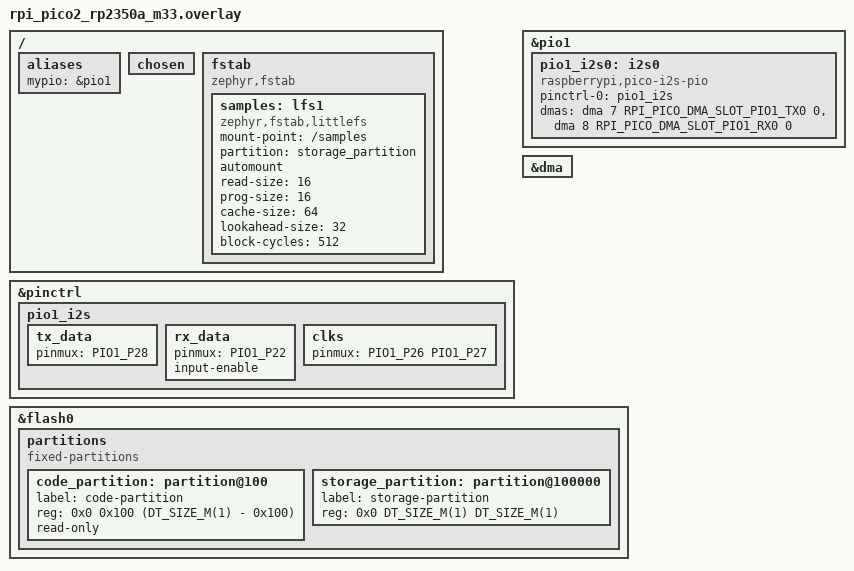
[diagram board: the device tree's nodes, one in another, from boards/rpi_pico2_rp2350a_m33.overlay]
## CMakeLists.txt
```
#-------------------------------------------------------------------------------
# Pocket Sampler Firmware 
#
# Copyright (c) 2021 Nordic Semiconductor ASA
# SPDX-License-Identifier: Apache-2.0

cmake_minimum_required(VERSION 3.13.1)
find_package(Zephyr REQUIRED HINTS $ENV{ZEPHYR_BASE})

project(app LANGUAGES C)

target_sources(app PRIVATE src/main.c)
```

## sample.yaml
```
sample:
  description: Pocket Sampler
  name: pocket-sampler 
common:
  build_only: true
  integration_platforms:
    - rp2040_zero
  depends_on:
    - usbd
tests:
  app.default: {}
  app.debug:
    extra_overlay_confs:
      - debug.conf
```

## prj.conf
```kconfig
CONFIG_GPIO=y

CONFIG_SHELL=y
CONFIG_GPIO_SHELL=y

CONFIG_FLASH=y
CONFIG_FLASH_MAP=y
CONFIG_FLASH_SHELL=y

CONFIG_FILE_SYSTEM=y
CONFIG_FILE_SYSTEM_LITTLEFS=y
CONFIG_FILE_SYSTEM_SHELL=y

CONFIG_DMA=y
CONFIG_I2S=y
CONFIG_COMPILER_SAVE_TEMPS=y

CONFIG_LOG=y
CONFIG_APP_LOG_LEVEL_DBG=y
CONFIG_I2S_LOG_LEVEL_DBG=y
CONFIG_DMA_LOG_LEVEL_DBG=y
CONFIG_FLASH_LOG_LEVEL_DBG=y
CONFIG_FS_LOG_LEVEL_DBG=y
```

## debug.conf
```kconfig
# Copyright (c) 2021 Nordic Semiconductor ASA
# SPDX-License-Identifier: Apache-2.0
#
# This is a Kconfig fragment which can be used to enable debug-related options
# in the application. See the README for more details.

# compiler
CONFIG_DEBUG_OPTIMIZATIONS=y

# native sim
CONFIG_EMUL=y
# CONFIG_FUSE_FS_ACCESS=y

# CONFIG_DISK_DRIVERS=y
# CONFIG_DISK_DRIVER_FLASH=y
# CONFIG_DISK_ACCESS=y
# CONFIG_FAT_FILESYSTEM_ELM=y
# CONFIG_MAIN_STACK_SIZE=2048

# logging
CONFIG_LOG=y
CONFIG_APP_LOG_LEVEL_DBG=y
CONFIG_DAC_LOG_LEVEL_OFF=y
```

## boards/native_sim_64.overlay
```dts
/ {
	aliases {
		mydac = &fake_dac;
	};
    fake_dac: dac_mock {
        compatible = "zephyr,dac-mock";
        status = "okay";
        #io-channel-cells = <1>;
    };

};
```

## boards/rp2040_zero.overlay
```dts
#include <dt-bindings/pinctrl/rpi-pico-rp2040-pinctrl.h>
#include <zephyr/dt-bindings/dma/rpi-pico-dma-rp2040.h>

/ {
	aliases {
		mypio = &pio1;
        
	};
	chosen {
		
    };
	
	fstab {
        compatible = "zephyr,fstab";
        samples: lfs1 {
            compatible = "zephyr,fstab,littlefs";
            mount-point = "/samples";
            partition = <&storage_partition>;
            automount;
            read-size = <16>;
            prog-size = <16>;
            cache-size = <64>;
            lookahead-size = <32>;
            block-cycles = <512>;
        };
    };
};


&pinctrl {
	pio1_i2s: pio1_i2s {
		tx_pins: tx_pins {
			//        DATA    CLK BASE  WS
			pinmux = <PIO1_P26 PIO1_P27 PIO1_P28>;
		};
	};

};

&pio1 { status = "okay";

	pio1_i2s0: i2s0 {
		pinctrl-0 = <&pio1_i2s>;
		pinctrl-names = "default";
		// TODO: Look over what these mean and that these values make sense
		#address-cells = <1>; 
		#size-cells = <0>;

		compatible = "raspberrypi,pico-i2s-pio";
		status = "okay";

		// TODO: Check how this works, but for now I believe that:
		//         channel      SLOT                  channel-config?
		//         number  (which corresponds to an IRQN)
		dmas = <&dma 7     RPI_PICO_DMA_SLOT_PIO1_TX0        0>;
		dma-names = "tx";
	};
};

&dma {
	status = "okay";
};

&flash0 {
	partitions {
		/*
		 * Usable flash. Starts at 0x100, after the bootloader. The partition
		 * size is 1MB minus the 0x100 bytes taken by the bootloader.
		 */
		code_partition: partition@100 {
			label = "code-partition";
			reg = <0x100 (DT_SIZE_M(1) - 0x100)>;
			read-only;
		};
		storage_partition: partition@100000 {
			label = "storage-partition";
			reg = <DT_SIZE_M(1) DT_SIZE_M(1)>;
		};
	};
};
```

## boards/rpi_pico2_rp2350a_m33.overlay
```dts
#include <dt-bindings/pinctrl/rpi-pico-rp2350a-pinctrl.h>
#include <zephyr/dt-bindings/dma/rpi-pico-dma-rp2350.h>

/ {
	aliases {
		mypio = &pio1;

	};
	chosen {

    };

	fstab {
        compatible = "zephyr,fstab";
        samples: lfs1 {
            compatible = "zephyr,fstab,littlefs";
            mount-point = "/samples";
            partition = <&storage_partition>;
            automount;
            read-size = <16>;
            prog-size = <16>;
            cache-size = <64>;
            lookahead-size = <32>;
            block-cycles = <512>;
        };
    };
};


&pinctrl {
	pio1_i2s: pio1_i2s {
		tx_data: tx_data {
			pinmux = <PIO1_P28>;
		};
		rx_data: rx_data {
			pinmux = <PIO1_P22>;
			/* Enable the pad input buffer so the PIO `in pins` can sample
			 * the external RX data line (off by default). */
			input-enable;
		};
		clks: clks {
			//        CLK BASE  (WS = CLK+1)
			pinmux = <PIO1_P26 PIO1_P27>;
		};
	};

};

&pio1 { status = "okay";

	pio1_i2s0: i2s0 {
		pinctrl-0 = <&pio1_i2s>;
		pinctrl-names = "default";
		// TODO: Look over what these mean and that these values make sense
		#address-cells = <1>;
		#size-cells = <0>;

		compatible = "raspberrypi,pico-i2s-pio";
		status = "okay";

		// TODO: Check how this works, but for now I believe that:
		//         channel      SLOT                  channel-config?
		//         number  (which corresponds to an IRQN)
		dmas = <&dma 7     RPI_PICO_DMA_SLOT_PIO1_TX0        0>,
    		   <&dma 8     RPI_PICO_DMA_SLOT_PIO1_RX0        0>;
		dma-names = "tx", "rx";
	};
};

&dma {
	status = "okay";
};

&flash0 {
	partitions {
		compatible = "fixed-partitions";
		/*
		 * Usable flash. Starts at 0x100, after the bootloader. The partition
		 * size is 1MB minus the 0x100 bytes taken by the bootloader.
		 */
		code_partition: partition@100 {
			label = "code-partition";
			reg = <0x0 0x100 (DT_SIZE_M(1) - 0x100)>;
			read-only;
		};
		storage_partition: partition@100000 {
			label = "storage-partition";
			reg = <0x0 DT_SIZE_M(1) DT_SIZE_M(1)>;
		};
	};
};
```

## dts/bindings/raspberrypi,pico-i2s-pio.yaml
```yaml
description: Raspberry Pi Pico PIO UART copy written by robin

compatible: "raspberrypi,pico-i2s-pio"

include: ["raspberrypi,pico-pio-device.yaml"]
# TODO: Does nothing right now i still need to figure out how to include it!!
```

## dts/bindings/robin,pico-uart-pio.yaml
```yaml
description: Raspberry Pi Pico PIO UART copy written by robin

compatible: "robin,pico-uart-pio"

include: [uart-controller.yaml, "raspberrypi,pico-pio-device.yaml"]
# TODO: Does nothing right now i still need to figure out how to include it!!
```

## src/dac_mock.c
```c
#include <zephyr/drivers/dac.h>
#include <zephyr/logging/log.h>

LOG_MODULE_REGISTER(dac_mock, CONFIG_DAC_LOG_LEVEL);

static int dac_mock_write_value(const struct device *dev, uint8_t channel, uint32_t value)
{
    LOG_INF("Mock DAC [%s]: Channel %d set to %u", dev->name, channel, value);
    return 0;
}

static int dac_mock_channel_setup(const struct device *dev, const struct dac_channel_cfg *channel_cfg)
{
    LOG_INF("Mock DAC [%s]: Channel %d setup with %d-bit resolution", 
             dev->name, channel_cfg->channel_id, channel_cfg->resolution);
    return 0;
}

static const struct dac_driver_api dac_mock_api = {
    .channel_setup = dac_mock_channel_setup,
    .write_value = dac_mock_write_value,
};

#define DT_DRV_COMPAT zephyr_dac_mock

#define DAC_MOCK_INIT(n) \
    DEVICE_DT_INST_DEFINE(n, NULL, NULL, NULL, NULL, \
                          POST_KERNEL, CONFIG_DAC_INIT_PRIORITY, \
                          &dac_mock_api);

DT_INST_FOREACH_STATUS_OKAY(DAC_MOCK_INIT)
```
